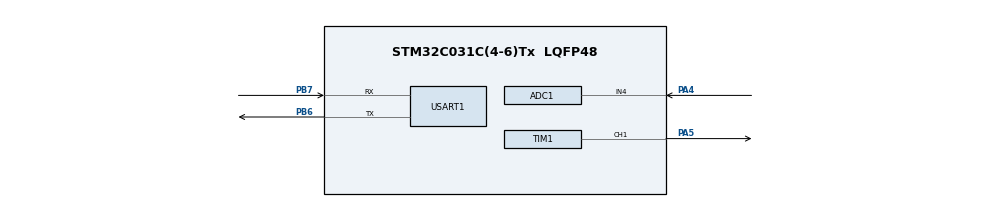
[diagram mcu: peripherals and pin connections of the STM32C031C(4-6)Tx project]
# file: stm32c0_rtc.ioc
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ADC1.Channel-0\#ChannelRegularConversion=ADC_CHANNEL_4
ADC1.Channel-1\#ChannelRegularConversion=ADC_CHANNEL_TEMPSENSOR
ADC1.Channel-2\#ChannelRegularConversion=ADC_CHANNEL_VREFINT
ADC1.ContinuousConvMode=ENABLE
ADC1.DMAContinuousRequests=ENABLE
ADC1.EnableAnalogWatchDog1=false
ADC1.ExternalTrigConv=ADC_SOFTWARE_START
ADC1.NbrOfConversion=3
ADC1.NbrOfConversionFlag=1
ADC1.OffsetNumber-0\#ChannelRegularConversion=ADC_OFFSET_NONE
ADC1.OffsetNumber-1\#ChannelRegularConversion=ADC_OFFSET_NONE
ADC1.OffsetNumber-2\#ChannelRegularConversion=ADC_OFFSET_NONE
ADC1.OversamplingMode=ENABLE
ADC1.Rank-0\#ChannelRegularConversion=1
ADC1.Rank-1\#ChannelRegularConversion=2
ADC1.Rank-2\#ChannelRegularConversion=3
ADC1.Ratio=ADC_OVERSAMPLING_RATIO_8
ADC1.RightBitShift=ADC_RIGHTBITSHIFT_3
ADC1.SamplingTime-0\#ChannelRegularConversion=ADC_SAMPLINGTIME_COMMON_1
ADC1.SamplingTime-1\#ChannelRegularConversion=ADC_SAMPLINGTIME_COMMON_1
ADC1.SamplingTime-2\#ChannelRegularConversion=ADC_SAMPLINGTIME_COMMON_1
ADC1.SamplingTimeCommon1=ADC_SAMPLETIME_160CYCLES_5
ADC1.SelectedChannel=ADC_CHANNEL_4|ADC_CHANNEL_TEMPSENSOR|ADC_CHANNEL_VREFINT
ADC1.Sequencer=FULLY_CONFIGURABLE
ADC1.TriggerFrequencyMode=ADC_TRIGGER_FREQ_HIGH
ADC1.WDGCONV1Channel1=__NULL
ADC1.master=1
Dma.ADC1.0.Direction=DMA_PERIPH_TO_MEMORY
Dma.ADC1.0.EventEnable=DISABLE
Dma.ADC1.0.Instance=DMA1_Channel1
Dma.ADC1.0.MemDataAlignment=DMA_MDATAALIGN_HALFWORD
Dma.ADC1.0.MemInc=DMA_MINC_ENABLE
Dma.ADC1.0.Mode=DMA_CIRCULAR
Dma.ADC1.0.PeriphDataAlignment=DMA_PDATAALIGN_HALFWORD
Dma.ADC1.0.PeriphInc=DMA_PINC_DISABLE
Dma.ADC1.0.Polarity=HAL_DMAMUX_REQ_GEN_RISING
Dma.ADC1.0.Priority=DMA_PRIORITY_LOW
Dma.ADC1.0.RequestNumber=1
Dma.ADC1.0.SignalID=NONE
Dma.ADC1.0.SyncEnable=DISABLE
Dma.ADC1.0.SyncPolarity=HAL_DMAMUX_SYNC_NO_EVENT
Dma.ADC1.0.SyncRequestNumber=1
Dma.ADC1.0.SyncSignalID=NONE
Dma.Request0=ADC1
Dma.Request1=USART1_RX
Dma.USART1_RX.1.Direction=DMA_PERIPH_TO_MEMORY
Dma.USART1_RX.1.EventEnable=DISABLE
Dma.USART1_RX.1.Instance=DMA1_Channel2
Dma.USART1_RX.1.MemDataAlignment=DMA_MDATAALIGN_BYTE
Dma.USART1_RX.1.MemInc=DMA_MINC_ENABLE
Dma.USART1_RX.1.Mode=DMA_CIRCULAR
Dma.USART1_RX.1.PeriphDataAlignment=DMA_PDATAALIGN_BYTE
Dma.USART1_RX.1.PeriphInc=DMA_PINC_DISABLE
Dma.USART1_RX.1.Polarity=HAL_DMAMUX_REQ_GEN_RISING
Dma.USART1_RX.1.Priority=DMA_PRIORITY_LOW
Dma.USART1_RX.1.RequestNumber=1
Dma.USART1_RX.1.SignalID=NONE
Dma.USART1_RX.1.SyncEnable=DISABLE
Dma.USART1_RX.1.SyncPolarity=HAL_DMAMUX_SYNC_NO_EVENT
Dma.USART1_RX.1.SyncRequestNumber=1
Dma.USART1_RX.1.SyncSignalID=NONE
Mcu.Family=STM32C0
Mcu.Name=STM32C031C(4-6)Tx
Mcu.Package=LQFP48
NVIC.TIM14_IRQn=true\:3\:0\:true\:false\:true\:true\:true\:true
PA13.Mode=Serial_Wire
PA13.Signal=DEBUG_SWDIO
PA14-BOOT0.Mode=Serial_Wire
PA14-BOOT0.Signal=DEBUG_SWCLK
PA4.Mode=IN4
PA4.Signal=ADC1_IN4
PA5.Signal=S_TIM1_CH1
PB6.Mode=Asynchronous
PB6.Signal=USART1_TX
PB7.Mode=Asynchronous
PB7.Signal=USART1_RX
PC14-OSCX_IN\ (PC14).Mode=LSE-External-Clock-Source
PC14-OSCX_IN\ (PC14).Signal=RCC_OSCX_IN
ProjectManager.HeapSize=0x200
ProjectManager.StackSize=0x400
ProjectManager.TargetToolchain=STM32CubeIDE
RCC.ADCFreq_Value=48000000
RCC.AHBFreq_Value=48000000
RCC.CortexFreq_Value=48000000
RCC.EXTERNAL_CLOCK_VALUE=12288000
RCC.HCLKFreq_Value=48000000
RCC.HSE_VALUE=8000000
RCC.HSISYSCLKDivider=RCC_HSI_DIV1
RCC.HSI_VALUE=48000000
RCC.LSE_VALUE=32768
RCC.PREFETCH_ENABLE=1
RCC.RTCClockSelection=RCC_RTCCLKSOURCE_LSE
RCC.SYSCLKFreq_VALUE=48000000
RTC.Format=RTC_FORMAT_BIN
SH.S_TIM1_CH1.0=TIM1_CH1,PWM Generation1 CH1
TIM1.Channel-PWM\ Generation1\ CH1=TIM_CHANNEL_1
TIM1.Period=99
TIM1.Prescaler=47
TIM14.Period=999
TIM14.Prescaler=47
USART1.VirtualMode-Asynchronous=VM_ASYNC
VP_ADC1_TempSens_Input.Mode=IN-TempSens
VP_ADC1_Vref_Input.Mode=IN-Vrefint
VP_RTC_VS_RTC_Activate.Mode=RTC_Enabled
VP_RTC_VS_RTC_Calendar.Mode=RTC_Calendar
VP_TIM14_VS_ClockSourceINT.Mode=Enable_Timer
VP_TIM1_VS_ClockSourceINT.Mode=Internal
board=custom

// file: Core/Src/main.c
/* USER CODE BEGIN Header */
/**
  ******************************************************************************
  * @file           : main.c
  * @brief          : Main program body
  ******************************************************************************
  * @attention
  *
  * Copyright (c) 2025 STMicroelectronics.
  * All rights reserved.
  *
  * This software is licensed under terms that can be found in the LICENSE file
  * in the root directory of this software component.
  * If no LICENSE file comes with this software, it is provided AS-IS.
  *
  ******************************************************************************
  */
/* USER CODE END Header */
#include "main.h"

/* USER CODE BEGIN Includes */
#include "ap.h"
/* USER CODE END Includes */

ADC_HandleTypeDef hadc1;
DMA_HandleTypeDef hdma_adc1;

RTC_HandleTypeDef hrtc;

TIM_HandleTypeDef htim1;
TIM_HandleTypeDef htim14;

UART_HandleTypeDef huart1;
DMA_HandleTypeDef hdma_usart1_rx;

void SystemClock_Config(void);
static void MX_GPIO_Init(void);
static void MX_DMA_Init(void);
static void MX_TIM1_Init(void);
static void MX_ADC1_Init(void);
static void MX_USART1_UART_Init(void);
static void MX_TIM14_Init(void);
static void MX_RTC_Init(void);

int main(void)
{

  /* MCU Configuration--------------------------------------------------------*/

  /* Reset of all peripherals, Initializes the Flash interface and the Systick. */
  HAL_Init();

  /* Configure the system clock */
  SystemClock_Config();

  /* Initialize all configured peripherals */
  MX_GPIO_Init();
  MX_DMA_Init();
  MX_TIM1_Init();
  MX_ADC1_Init();
  MX_USART1_UART_Init();
  MX_TIM14_Init();
  MX_RTC_Init();
  /* USER CODE BEGIN 2 */
  apInit();
  apMain();
  /* USER CODE END 2 */

  /* Infinite loop */
  while (1)
  {

  }
}

void SystemClock_Config(void)
{
  LL_FLASH_EnablePrefetch();

  LL_FLASH_SetLatency(LL_FLASH_LATENCY_1);

  /* HSI configuration and activation */
  LL_RCC_HSI_Enable();
  while(LL_RCC_HSI_IsReady() != 1)
  {
  }

  LL_RCC_HSI_SetCalibTrimming(64);
  LL_RCC_SetHSIDiv(LL_RCC_HSI_DIV_1);
  /* LSE configuration and activation */
  LL_RCC_LSE_EnableBypass();
  LL_RCC_LSE_Enable();
  while(LL_RCC_LSE_IsReady() != 1)
  {
  }

  /* Set AHB prescaler*/
  LL_RCC_SetAHBPrescaler(LL_RCC_HCLK_DIV_1);

  /* Sysclk activation on the HSI */
  LL_RCC_SetSysClkSource(LL_RCC_SYS_CLKSOURCE_HSI);
  while(LL_RCC_GetSysClkSource() != LL_RCC_SYS_CLKSOURCE_STATUS_HSI)
  {
  }

  /* Set APB1 prescaler*/
  LL_RCC_SetAPB1Prescaler(LL_RCC_APB1_DIV_1);
  /* Update CMSIS variable (which can be updated also through SystemCoreClockUpdate function) */
  LL_SetSystemCoreClock(48000000);

   /* Update the time base */
  if (HAL_InitTick (TICK_INT_PRIORITY) != HAL_OK)
  {
    Error_Handler();
  }
}

static void MX_ADC1_Init(void)
{

  ADC_ChannelConfTypeDef sConfig = {0};

  /** Configure the global features of the ADC (Clock, Resolution, Data Alignment and number of conversion)
  */
  hadc1.Instance = ADC1;
  hadc1.Init.ClockPrescaler = ADC_CLOCK_SYNC_PCLK_DIV2;
  hadc1.Init.Resolution = ADC_RESOLUTION_12B;
  hadc1.Init.DataAlign = ADC_DATAALIGN_RIGHT;
  hadc1.Init.ScanConvMode = ADC_SCAN_ENABLE;
  hadc1.Init.EOCSelection = ADC_EOC_SINGLE_CONV;
  hadc1.Init.LowPowerAutoWait = DISABLE;
  hadc1.Init.LowPowerAutoPowerOff = DISABLE;
  hadc1.Init.ContinuousConvMode = ENABLE;
  hadc1.Init.NbrOfConversion = 3;
  hadc1.Init.ExternalTrigConv = ADC_SOFTWARE_START;
  hadc1.Init.ExternalTrigConvEdge = ADC_EXTERNALTRIGCONVEDGE_NONE;
  hadc1.Init.DMAContinuousRequests = ENABLE;
  hadc1.Init.Overrun = ADC_OVR_DATA_PRESERVED;
  hadc1.Init.SamplingTimeCommon1 = ADC_SAMPLETIME_160CYCLES_5;
  hadc1.Init.SamplingTimeCommon2 = ADC_SAMPLETIME_1CYCLE_5;
  hadc1.Init.OversamplingMode = ENABLE;
  hadc1.Init.Oversampling.Ratio = ADC_OVERSAMPLING_RATIO_8;
  hadc1.Init.Oversampling.RightBitShift = ADC_RIGHTBITSHIFT_3;
  hadc1.Init.Oversampling.TriggeredMode = ADC_TRIGGEREDMODE_SINGLE_TRIGGER;
  hadc1.Init.TriggerFrequencyMode = ADC_TRIGGER_FREQ_HIGH;
  if (HAL_ADC_Init(&hadc1) != HAL_OK)
  {
    Error_Handler();
  }

  /** Configure Regular Channel
  */
  sConfig.Channel = ADC_CHANNEL_4;
  sConfig.Rank = ADC_REGULAR_RANK_1;
  sConfig.SamplingTime = ADC_SAMPLINGTIME_COMMON_1;
  if (HAL_ADC_ConfigChannel(&hadc1, &sConfig) != HAL_OK)
  {
    Error_Handler();
  }

  /** Configure Regular Channel
  */
  sConfig.Channel = ADC_CHANNEL_TEMPSENSOR;
  sConfig.Rank = ADC_REGULAR_RANK_2;
  if (HAL_ADC_ConfigChannel(&hadc1, &sConfig) != HAL_OK)
  {
    Error_Handler();
  }

  /** Configure Regular Channel
  */
  sConfig.Channel = ADC_CHANNEL_VREFINT;
  sConfig.Rank = ADC_REGULAR_RANK_3;
  if (HAL_ADC_ConfigChannel(&hadc1, &sConfig) != HAL_OK)
  {
    Error_Handler();
  }

}

static void MX_RTC_Init(void)
{

  RTC_TimeTypeDef sTime = {0};
  RTC_DateTypeDef sDate = {0};

  /** Initialize RTC Only
  */
  hrtc.Instance = RTC;
  hrtc.Init.HourFormat = RTC_HOURFORMAT_24;
  hrtc.Init.AsynchPrediv = 127;
  hrtc.Init.SynchPrediv = 255;
  hrtc.Init.OutPut = RTC_OUTPUT_DISABLE;
  hrtc.Init.OutPutRemap = RTC_OUTPUT_REMAP_NONE;
  hrtc.Init.OutPutPolarity = RTC_OUTPUT_POLARITY_HIGH;
  hrtc.Init.OutPutType = RTC_OUTPUT_TYPE_OPENDRAIN;
  hrtc.Init.OutPutPullUp = RTC_OUTPUT_PULLUP_NONE;
  if (HAL_RTC_Init(&hrtc) != HAL_OK)
  {
    Error_Handler();
  }

  /** Initialize RTC and set the Time and Date
  */
  sTime.Hours = 0;
  sTime.Minutes = 0;
  sTime.Seconds = 0;
  sTime.SubSeconds = 0;
  sTime.DayLightSaving = RTC_DAYLIGHTSAVING_NONE;
  sTime.StoreOperation = RTC_STOREOPERATION_RESET;
  if (HAL_RTC_SetTime(&hrtc, &sTime, RTC_FORMAT_BIN) != HAL_OK)
  {
    Error_Handler();
  }
  sDate.WeekDay = RTC_WEEKDAY_MONDAY;
  sDate.Month = RTC_MONTH_JANUARY;
  sDate.Date = 1;
  sDate.Year = 0;

  if (HAL_RTC_SetDate(&hrtc, &sDate, RTC_FORMAT_BIN) != HAL_OK)
  {
    Error_Handler();
  }

}

static void MX_TIM1_Init(void)
{

  TIM_ClockConfigTypeDef sClockSourceConfig = {0};
  TIM_MasterConfigTypeDef sMasterConfig = {0};
  TIM_OC_InitTypeDef sConfigOC = {0};
  TIM_BreakDeadTimeConfigTypeDef sBreakDeadTimeConfig = {0};

  htim1.Instance = TIM1;
  htim1.Init.Prescaler = 47;
  htim1.Init.CounterMode = TIM_COUNTERMODE_UP;
  htim1.Init.Period = 99;
  htim1.Init.ClockDivision = TIM_CLOCKDIVISION_DIV1;
  htim1.Init.RepetitionCounter = 0;
  htim1.Init.AutoReloadPreload = TIM_AUTORELOAD_PRELOAD_DISABLE;
  if (HAL_TIM_Base_Init(&htim1) != HAL_OK)
  {
    Error_Handler();
  }
  sClockSourceConfig.ClockSource = TIM_CLOCKSOURCE_INTERNAL;
  if (HAL_TIM_ConfigClockSource(&htim1, &sClockSourceConfig) != HAL_OK)
  {
    Error_Handler();
  }
  if (HAL_TIM_PWM_Init(&htim1) != HAL_OK)
  {
    Error_Handler();
  }
  sMasterConfig.MasterOutputTrigger = TIM_TRGO_RESET;
  sMasterConfig.MasterOutputTrigger2 = TIM_TRGO2_RESET;
  sMasterConfig.MasterSlaveMode = TIM_MASTERSLAVEMODE_DISABLE;
  if (HAL_TIMEx_MasterConfigSynchronization(&htim1, &sMasterConfig) != HAL_OK)
  {
    Error_Handler();
  }
  sConfigOC.OCMode = TIM_OCMODE_PWM1;
  sConfigOC.Pulse = 0;
  sConfigOC.OCPolarity = TIM_OCPOLARITY_HIGH;
  sConfigOC.OCNPolarity = TIM_OCNPOLARITY_HIGH;
  sConfigOC.OCFastMode = TIM_OCFAST_DISABLE;
  sConfigOC.OCIdleState = TIM_OCIDLESTATE_RESET;
  sConfigOC.OCNIdleState = TIM_OCNIDLESTATE_RESET;
  if (HAL_TIM_PWM_ConfigChannel(&htim1, &sConfigOC, TIM_CHANNEL_1) != HAL_OK)
  {
    Error_Handler();
  }
  sBreakDeadTimeConfig.OffStateRunMode = TIM_OSSR_DISABLE;
  sBreakDeadTimeConfig.OffStateIDLEMode = TIM_OSSI_DISABLE;
  sBreakDeadTimeConfig.LockLevel = TIM_LOCKLEVEL_OFF;
  sBreakDeadTimeConfig.DeadTime = 0;
  sBreakDeadTimeConfig.BreakState = TIM_BREAK_DISABLE;
  sBreakDeadTimeConfig.BreakPolarity = TIM_BREAKPOLARITY_HIGH;
  sBreakDeadTimeConfig.BreakFilter = 0;
  sBreakDeadTimeConfig.BreakAFMode = TIM_BREAK_AFMODE_INPUT;
  sBreakDeadTimeConfig.Break2State = TIM_BREAK2_DISABLE;
  sBreakDeadTimeConfig.Break2Polarity = TIM_BREAK2POLARITY_HIGH;
  sBreakDeadTimeConfig.Break2Filter = 0;
  sBreakDeadTimeConfig.Break2AFMode = TIM_BREAK_AFMODE_INPUT;
  sBreakDeadTimeConfig.AutomaticOutput = TIM_AUTOMATICOUTPUT_DISABLE;
  if (HAL_TIMEx_ConfigBreakDeadTime(&htim1, &sBreakDeadTimeConfig) != HAL_OK)
  {
    Error_Handler();
  }
  HAL_TIM_MspPostInit(&htim1);

}

static void MX_TIM14_Init(void)
{

  htim14.Instance = TIM14;
  htim14.Init.Prescaler = 47;
  htim14.Init.CounterMode = TIM_COUNTERMODE_UP;
  htim14.Init.Period = 999;
  htim14.Init.ClockDivision = TIM_CLOCKDIVISION_DIV1;
  htim14.Init.AutoReloadPreload = TIM_AUTORELOAD_PRELOAD_DISABLE;
  if (HAL_TIM_Base_Init(&htim14) != HAL_OK)
  {
    Error_Handler();
  }

}

static void MX_USART1_UART_Init(void)
{

  huart1.Instance = USART1;
  huart1.Init.BaudRate = 115200;
  huart1.Init.WordLength = UART_WORDLENGTH_8B;
  huart1.Init.StopBits = UART_STOPBITS_1;
  huart1.Init.Parity = UART_PARITY_NONE;
  huart1.Init.Mode = UART_MODE_TX_RX;
  huart1.Init.HwFlowCtl = UART_HWCONTROL_NONE;
  huart1.Init.OverSampling = UART_OVERSAMPLING_16;
  huart1.Init.OneBitSampling = UART_ONE_BIT_SAMPLE_DISABLE;
  huart1.Init.ClockPrescaler = UART_PRESCALER_DIV1;
  huart1.AdvancedInit.AdvFeatureInit = UART_ADVFEATURE_NO_INIT;
  if (HAL_UART_Init(&huart1) != HAL_OK)
  {
    Error_Handler();
  }
  if (HAL_UARTEx_SetTxFifoThreshold(&huart1, UART_TXFIFO_THRESHOLD_1_8) != HAL_OK)
  {
    Error_Handler();
  }
  if (HAL_UARTEx_SetRxFifoThreshold(&huart1, UART_RXFIFO_THRESHOLD_1_8) != HAL_OK)
  {
    Error_Handler();
  }
  if (HAL_UARTEx_DisableFifoMode(&huart1) != HAL_OK)
  {
    Error_Handler();
  }

}

static void MX_DMA_Init(void)
{

  /* DMA controller clock enable */
  __HAL_RCC_DMA1_CLK_ENABLE();

}

static void MX_GPIO_Init(void)
{

  /* GPIO Ports Clock Enable */
  __HAL_RCC_GPIOC_CLK_ENABLE();
  __HAL_RCC_GPIOA_CLK_ENABLE();
  __HAL_RCC_GPIOB_CLK_ENABLE();

}

void Error_Handler(void)
{
  __disable_irq();
  while (1)
  {
  }
}
